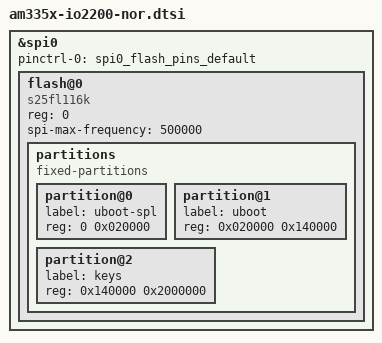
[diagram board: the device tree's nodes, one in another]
&spi0 {
	pinctrl-names = "default";
	pinctrl-0 = <&spi0_flash_pins_default>;
	status = "okay";

	flash@0 {
		compatible = "s25fl116k", "is25lp016", "mx25l1606e", "jedec,spi-nor";
		reg = <0>;
		spi-max-frequency = <500000>;
		status = "okay";

		partitions {
			compatible = "fixed-partitions";
			#address-cells = <1>;
			#size-cells = <1>;

			partition@0 {
				label = "uboot-spl";
				reg   = <0 0x020000>;
			};
			partition@1 {
				label = "uboot";
				reg   = <0x020000 0x140000>;
			};
			partition@2 {
				label = "keys";
				reg   = <0x140000 0x2000000>;
			};
		};
	};
};
